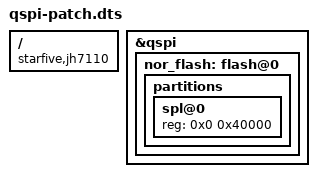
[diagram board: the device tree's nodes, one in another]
/dts-v1/;
/plugin/;
/ {
    compatible = "starfive,jh7110";
    fragment@0 {
        target = <&qspi>;
        __overlay__ {
            nor_flash: flash@0 {
                partitions {
                    spl@0 {
                        reg = <0x0 0x40000>;
                    };
                };
            };
        };
    };
};
